# nrf54h20_enga_application register map
Vendor: Nordic Semiconductor; Series: nRF54h; File version: 1
CPU: CM33 r0p4, little endian, MPU, FPU, 3 interrupt priority bits, 480 interrupts, 4 SAU regions
Registers are 32-bit, read-write, reset 0x0 unless marked. A register's access mark holds for its fields unless they carry their own. Offsets are from the block's base; [hi:lo] are bit positions; lines under a group give offsets from that group; {n}, {i} and the like mark numbered series; 'fields as' and 'values as' point back to an identical list.

## ICACHEDATA_S — CACHEDATA 0
Base 0x12F00000
Same registers: DCACHEDATA_S 0x32F00000
{0x0+0x40*i} SET[{i}] (i=0..255) group — Unspecified
  {0x0+0x20*j} WAY[{j}] (j=0..1) group — Unspecified
    {0x0+8k} DU[{k}] (k=0..3) group — Unspecified
      {0x0+4l} DATA[{l}] (l=0..1) — Description collection: Cache data bits for DATA[q] in DU[p] (DataUnit) of SET[n], WAY[o].
        [31:0] Data ro

## ICACHEINFO_S — CACHEINFO 0
Base 0x12F10000
Same registers: DCACHEINFO_S 0x32F10000
{0x0+8i} SET[{i}] (i=0..255) group — Unspecified
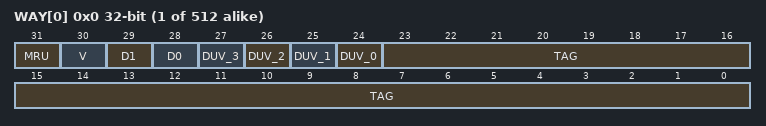
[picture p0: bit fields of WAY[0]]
  {0x0+4j} WAY[{j}] (j=0..1) — Description collection: Cache information for SET[n], WAY[o].
    [31] MRU ro — Most recently used way.
      0=Way0 was most recently used; 1=Way1 was most recently used
    [30] V ro — Line valid bit.
      0=Invalid cache line; 1=Valid cache line
    [29] D1 ro — Dirty data unit 1.
      0=Clean data unit; 1=Dirty data unit
    [28] D0 ro — Dirty data unit 0.
      0=Clean data unit; 1=Dirty data unit
    [n+24] DUV_{n} ro (n=0..3) — Data unit valid info.
      0=Invalid data unit; 1=Valid data unit
    [23:0] TAG ro — Cache tag.

## GLOBAL_STMDATA_NS — System Trace Macrocell data buffer 0
Base 0xA0000000
Same registers: GLOBAL_STMDATA_S 0xA0000000 (alternate view of GLOBAL_STMDATA_NS)
{0x0+0x2000000*i} DOMAIN[{i}] (i=0..15) group — Unspecified
  {0x0+j} NSDATA[{j}] (j=0..16777215) 8-bit — Description collection: NonSecure STM output data buffer for domain n. Writes to this region generates trace packets with id n+96.
  {0x1000000+j} SDATA[{j}] (j=0..16777215) 8-bit — Description collection: Secure STM output data buffer for domain n. Writes to this region generates trace packets with id n+32.

## GLOBAL_TDDCONF_NS — TDDCONF 0
Base 0xBF001000
Same registers: GLOBAL_TDDCONF_S 0xBF001000 (alternate view of GLOBAL_TDDCONF_NS)
0x400 SYSPWRUPREQ — System power-up request
  [0] ACTIVE — Activate power-up request
    0=NotActive (Power-up request not active); 1=Active (Power-up request active)
0x404 DBGPWRUPREQ — Debug power-up request
  fields as SYSPWRUPREQ
0x408 TRACEPORTSPEED — Trace port trace clock speed
  [1:0] SPEED — Trace clock speed
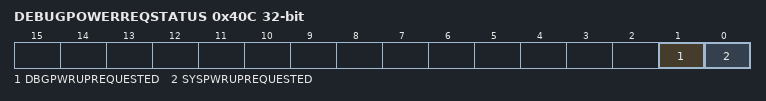
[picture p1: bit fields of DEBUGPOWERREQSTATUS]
0x40C DEBUGPOWERREQSTATUS ro — Combined effective system status of both SWJ-DP and TDDCONF registers originated power requests
  [1] DBGPWRUPREQUESTED — Debug domain powerup request status
    0=NoPowerReq (Power not requested); 1=Power requested
  [0] SYSPWRUPREQUESTED — System powerup request status
    0=NoPowerReq (Power not requested); 1=Power requested

## CPUC_S — CM33 SubSystem
Base 0xE0080000
0x100 EVENTS_FPUIOC — An invalid operation exception has occurred in the FPU.
  [0] EVENTS_FPUIOC
    0=NotGenerated (Event not generated); 1=Generated (Event generated)
0x104 EVENTS_FPUDZC — A floating-point divide-by-zero exception has occurred in the FPU.
  [0] EVENTS_FPUDZC
    values as EVENTS_FPUIOC.EVENTS_FPUIOC
0x108 EVENTS_FPUOFC — A floating-point overflow exception has occurred in the FPU.
  [0] EVENTS_FPUOFC
    values as EVENTS_FPUIOC.EVENTS_FPUIOC
0x10C EVENTS_FPUUFC — A floating-point underflow exception has occurred in the FPU.
  [0] EVENTS_FPUUFC
    values as EVENTS_FPUIOC.EVENTS_FPUIOC
0x110 EVENTS_FPUIXC — A floating-point inexact exception has occurred in the FPU.
  [0] EVENTS_FPUIXC
    values as EVENTS_FPUIOC.EVENTS_FPUIOC
0x114 EVENTS_FPUIDC — A floating-point input denormal exception has occurred in the FPU.
  [0] EVENTS_FPUIDC
    values as EVENTS_FPUIOC.EVENTS_FPUIOC
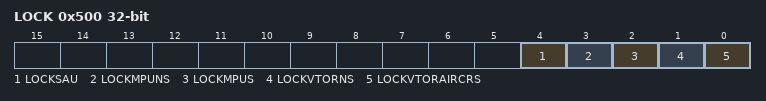
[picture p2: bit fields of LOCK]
0x500 LOCK — Register to lock the certain parts of the CPU from being modified.
  [4] LOCKSAU — Locks the Security Attribution Unit (SAU)
    0=NotLocked (SAU registers can be changed.); 1=Locked (Prevents changes to SAU registers.)
  [3] LOCKMPUNS — Locks the Memory Protection Unit (MPU) for non secure mode.
    0=NotLocked (MPU registers can be changed.); 1=Locked (Prevents changes to MPU registers.)
  [2] LOCKMPUS — Locks the Memory Protection Unit (MPU) for secure mode.
    values as LOCKMPUNS
  [1] LOCKVTORNS — Locks the Vector table Offset Register (VTOR) for non-secure mode.
    0=NotLocked (VTOR can be changed.); 1=Locked (Prevents changes to VTOR.)
  [0] LOCKVTORAIRCRS — Locks both the Vector table Offset Register (VTOR) and Application Interrupt and Reset Control Register (AIRCR) for secure mode.
    0=NotLocked (Both VTOR and AIRCR can be changed.); 1=Locked (Prevents changes to both VTOR and AIRCR.)
0x504 CPUID ro — The identifier for the CPU in this subsystem.
  [31:0] CPUID — The CPU identifier.
